VERSION ""

NS_ :

BS_:

BU_: eCallGateway eCallTCU

BO_ 1288 msgVehicleIdentity: 8 eCallGateway
 SG_ sigVinFraction : 0|64@1+ (1,0) [0|1.84467440737096E+019] ""  eCallTCU

BO_ 1286 msgVehicleCfg: 8 eCallGateway
 SG_ sigVehicleType : 8|8@1+ (1,0) [0|255] ""  eCallTCU
 SG_ sigPropulsionType : 0|8@1+ (1,0) [0|255] ""  eCallTCU

BO_ 1791 msgDiagReqFunc: 8 eCallGateway
 SG_ sigDiagReq : 0|64@1+ (1,0) [0|0] ""  eCallTCU

BO_ 1618 msgDiagResp: 8 eCallTCU
 SG_ sigDiagResp : 0|64@1+ (1,0) [0|0] ""  eCallGateway

BO_ 1616 msgDiagReq: 8 eCallGateway
 SG_ sigDiagReq : 0|64@1+ (1,0) [0|0] ""  eCallTCU

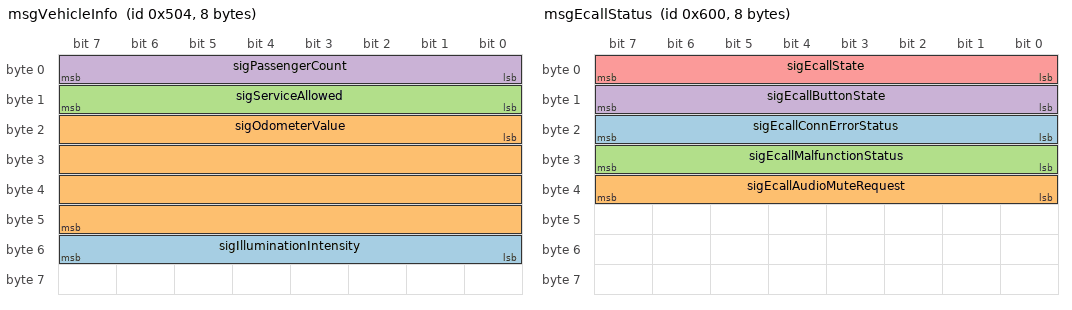
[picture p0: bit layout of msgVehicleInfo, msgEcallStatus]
BO_ 1284 msgVehicleInfo: 8 eCallGateway
 SG_ sigIlluminationIntensity : 48|8@1+ (1,0) [0|255] ""  eCallTCU
 SG_ sigOdometerValue : 16|32@1+ (1,0) [0|4294967295] "m"  eCallTCU
 SG_ sigServiceAllowed : 8|8@1+ (1,0) [0|255] ""  eCallTCU
 SG_ sigPassengerCount : 0|8@1+ (1,0) [0|255] ""  eCallTCU

BO_ 1282 msgVehicleState: 8 eCallGateway
 SG_ sigVehicleState : 0|8@1+ (1,0) [0|255] ""  eCallTCU

BO_ 1280 msgCrashNotification: 8 eCallGateway
 SG_ sigCrashStatus : 0|8@1+ (1,0) [0|255] ""  eCallTCU

BO_ 1536 msgEcallStatus: 8 eCallTCU
 SG_ sigEcallConnErrorStatus : 16|8@1+ (1,0) [0|255] ""  eCallGateway
 SG_ sigEcallAudioMuteRequest : 32|8@1+ (1,0) [0|255] ""  eCallGateway
 SG_ sigEcallMalfunctionStatus : 24|8@1+ (1,0) [0|255] ""  eCallGateway
 SG_ sigEcallButtonState : 8|8@1+ (1,0) [0|255] ""  eCallGateway
 SG_ sigEcallState : 0|8@1+ (1,0) [0|255] ""  eCallGateway

CM_ "$File: //depot/auto/dbc/Third_party_components/Actia/ecall/0.2.1.0/Actia_eCall_CAN.dbc $
$Change: 215987 $
$DateTime: 2024/08/21 10:13:29 $
$Revision: #1 $";
CM_ SG_ 1288 sigVinFraction "The signal data is divided into 3 separate blocks transmitted in a sequential loop (8-byte record: block counter (MSB) + 7 ASCII characters)
Block cntr 0x01: VIN 1-7
Block cntr 0x02: VIN 8-14
Block cntr 0x03: VIN 15-17
Block cntr 0xff: any fault";
CM_ SG_ 1286 sigPropulsionType "It is possible to set more than one bit in the data byte in case the vehicle supports more than one propulsion type.";
CM_ SG_ 1284 sigIlluminationIntensity "0xFF is interpreted as invalid/unknown";
CM_ SG_ 1284 sigOdometerValue "0xFFFFFFFF is interpreted as invalid/unknown";
CM_ SG_ 1284 sigPassengerCount "0xFF is interpreted as invalid/unknown";
BA_DEF_ BU_  "ECU" STRING ;
BA_DEF_ BO_  "GenMsgCycleTime" INT 0 3600000;
BA_DEF_  "BusType" STRING ;
BA_DEF_ BO_  "Producer" STRING ;
BA_DEF_DEF_  "ECU" "";
BA_DEF_DEF_  "GenMsgCycleTime" 0;
BA_DEF_DEF_  "BusType" "";
BA_ "BusType" "CAN";
BA_ "ECU" BU_ eCallGateway "eCallGateway";
BA_ "ECU" BU_ eCallTCU "eCallTCU";
BA_ "GenMsgCycleTime" BO_ 1288 100;
BA_ "GenMsgCycleTime" BO_ 1286 100;
BA_ "GenMsgCycleTime" BO_ 1284 100;
BA_ "GenMsgCycleTime" BO_ 1282 100;
BA_ "GenMsgCycleTime" BO_ 1280 20;
BA_ "GenMsgCycleTime" BO_ 1536 100;
BA_ "Producer" BO_ 1280 "SFT";
BA_ "Producer" BO_ 1282 "SFT";
BA_ "Producer" BO_ 1284 "SFT";
BA_ "Producer" BO_ 1286 "SFT";
BA_ "Producer" BO_ 1288 "SFT";
VAL_ 1286 sigVehicleType 13 "Motorcycles L7e" 12 "Motorcycles L6e" 11 "Motorcycles L5e" 10 "Motorcycles L4e" 9 "Motorcycles L3e" 8 "Motorcycles L2e" 7 "Motorcycles L1e" 6 "Heavy duty vehicles N3" 5 "Heavy duty vehicles N2" 4 "Light commercial vehicles N1" 3 "Buses and coaches M3" 2 "Buses and coaches M2" 1 "Passenger vehicle M1" ;
VAL_ 1286 sigPropulsionType 64 "Other" 32 "Hydrogen" 16 "Electric" 8 "LPG" 4 "CNG" 2 "Diesel" 1 "Gasoline" ;
VAL_ 1284 sigServiceAllowed 3 "ManualAndAutomaticEcallAllowed" 2 "AutomaticEcallOnlyAllowed" 1 "ManualEcallOnlyAllowed" 0 "NoEcallAllowed" ;
VAL_ 1282 sigVehicleState 2 "Running" 1 "Awake" 0 "Sleep" ;
VAL_ 1280 sigCrashStatus 2 "Unknown" 1 "Crash" 0 "NoCrash" ;
VAL_ 1536 sigEcallConnErrorStatus 1 "Error" 0 "Ok" ;
VAL_ 1536 sigEcallAudioMuteRequest 1 "Mute" 0 "Unmute" ;
VAL_ 1536 sigEcallMalfunctionStatus 1 "Malfunction" 0 "No problem diagnosed" ;
VAL_ 1536 sigEcallButtonState 1 "Pressed" 0 "Released" ;
VAL_ 1536 sigEcallState 3 "Connected" 2 "Connecting" 1 "Confirm" 0 "Inactive" ;
